VERSION ""

NS_ :

BS_:

BU_: UUT CTRL

BO_ 3221225472 VECTOR__INDEPENDENT_SIG_MSG: 0 Vector__XXX
 SG_ DutyCycle_SP_Input1A : 16|16@1+ (1,0) [0|0] "" Vector__XXX
 SG_ DutyCycle_SP_Input1B : 48|16@1+ (1,0) [0|0] "" Vector__XXX
 SG_ DutyCycle_SP_Input3A : 16|16@1+ (1,0) [0|0] "" Vector__XXX
 SG_ DutyCycle_SP_Input3B : 48|16@1+ (1,0) [0|0] "" Vector__XXX
 SG_ LowBYTE_Counter_1A_Setpoint m87 : 32|16@1+ (1,0) [0|0] "" Vector__XXX
 SG_ LowBYTE_Counter_3A_Setpoint m87 : 48|16@1+ (1,0) [0|0] "" Vector__XXX

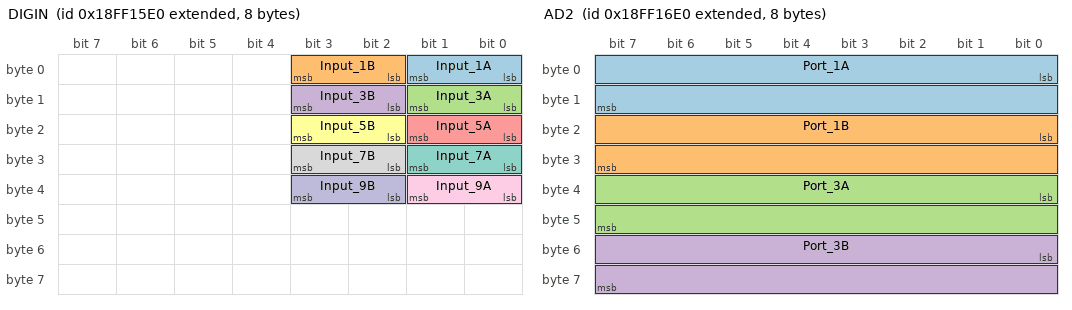
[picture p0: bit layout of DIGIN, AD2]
BO_ 2566854112 DIGIN: 8 UUT
 SG_ Input_1A : 0|2@1+ (1,0) [0|0] "" Vector__XXX
 SG_ Input_1B : 2|2@1+ (1,0) [0|0] "" Vector__XXX
 SG_ Input_3A : 8|2@1+ (1,0) [0|0] "" Vector__XXX
 SG_ Input_3B : 10|2@1+ (1,0) [0|0] "" Vector__XXX
 SG_ Input_5A : 16|2@1+ (1,0) [0|0] "" Vector__XXX
 SG_ Input_5B : 18|2@1+ (1,0) [0|0] "" Vector__XXX
 SG_ Input_7A : 24|2@1+ (1,0) [0|0] "" Vector__XXX
 SG_ Input_7B : 26|2@1+ (1,0) [0|0] "" Vector__XXX
 SG_ Input_9A : 32|2@1+ (1,0) [0|0] "" Vector__XXX
 SG_ Input_9B : 34|2@1+ (1,0) [0|0] "" Vector__XXX

BO_ 2566854368 AD2: 8 UUT
 SG_ Port_1A : 0|16@1+ (0.001,0) [0|0] "" Vector__XXX
 SG_ Port_1B : 16|16@1+ (0.001,0) [0|0] "" Vector__XXX
 SG_ Port_3A : 32|16@1+ (0.001,0) [0|0] "" Vector__XXX
 SG_ Port_3B : 48|16@1+ (0.001,0) [0|0] "" Vector__XXX

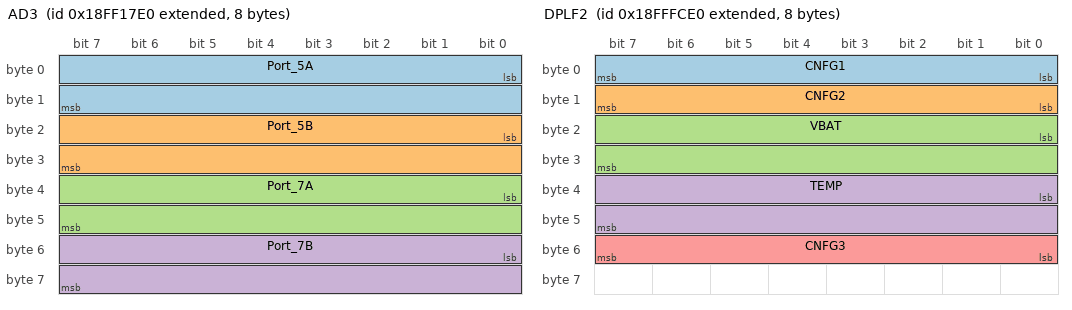
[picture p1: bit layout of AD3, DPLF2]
BO_ 2566854624 AD3: 8 UUT
 SG_ Port_5A : 0|16@1+ (0.001,0) [0|0] "" Vector__XXX
 SG_ Port_5B : 16|16@1+ (0.001,0) [0|0] "" Vector__XXX
 SG_ Port_7A : 32|16@1+ (0.001,0) [0|0] "" Vector__XXX
 SG_ Port_7B : 48|16@1+ (0.001,0) [0|0] "" Vector__XXX

BO_ 2566854880 AD4: 8 UUT
 SG_ Port_9A : 0|16@1+ (0.001,0) [0|0] "" Vector__XXX
 SG_ Port_9B : 16|16@1+ (0.001,0) [0|0] "" Vector__XXX

BO_ 2566855392 FREQ1: 8 UUT
 SG_ Hertz_Count_Input1A : 0|16@1+ (1,0) [0|0] "" Vector__XXX
 SG_ Hertz_Count_Input1B : 32|16@1+ (1,0) [0|0] "" Vector__XXX
 SG_ EncoderValue1 : 0|32@1+ (1,0) [0|0] "" Vector__XXX

BO_ 2566855648 FREQ2: 8 UUT
 SG_ Count_Input3A : 0|16@1+ (1,0) [0|0] "" Vector__XXX
 SG_ Count_Input3B : 32|16@1+ (1,0) [0|0] "" Vector__XXX
 SG_ EncoderValue3 : 0|32@1+ (1,0) [0|0] "" Vector__XXX

BO_ 2565853664 STAT: 8 UUT
 SG_ Software_Version : 0|8@1+ (1,0) [0|0] "" Vector__XXX
 SG_ Software_Revision : 8|8@1+ (1,0) [0|0] "" Vector__XXX
 SG_ Factory_Default_Configuration : 16|2@1+ (1,0) [0|0] "" Vector__XXX
 SG_ Configuration_Saved : 18|2@1+ (1,0) [0|0] "" Vector__XXX
 SG_ Alternate_Configuration_Saved : 20|2@1+ (1,0) [0|0] "" Vector__XXX
 SG_ Node_Alive : 22|2@1+ (1,0) [0|0] "" Vector__XXX
 SG_ Node_Fault_Present : 24|2@1+ (1,0) [0|0] "" Vector__XXX
 SG_ Fault_Counter_Not_Zero : 26|2@1+ (1,0) [0|0] "" Vector__XXX
 SG_ Active_Fault_Code : 32|8@1+ (1,0) [0|0] "" Vector__XXX
 SG_ UserID : 40|8@1+ (1,0) [0|0] "" Vector__XXX
 SG_ CMND_52h_RCVD : 48|2@1+ (1,0) [0|0] "" Vector__XXX
 SG_ CMND_53h_RCVD : 50|2@1+ (1,0) [0|0] "" Vector__XXX
 SG_ CMND_54h_RCVD : 52|2@1+ (1,0) [0|0] "" Vector__XXX
 SG_ CMND_55h_RCVD : 54|2@1+ (1,0) [0|0] "" Vector__XXX
 SG_ CMND_56h_RCVD : 56|2@1+ (1,0) [0|0] "" Vector__XXX
 SG_ CMND_57h_RCVD : 58|2@1+ (1,0) [0|0] "" Vector__XXX
 SG_ Hardware_Dash : 60|4@1+ (1,0) [0|0] "" Vector__XXX

BO_ 2566912992 DPLF1: 8 UUT
 SG_ Input_1_BAUD1 : 0|2@1+ (1,0) [0|0] "" Vector__XXX
 SG_ Input_2_BAUD2 : 2|2@1+ (1,0) [0|0] "" Vector__XXX
 SG_ Input_3_CNFG_IN1 : 4|2@1+ (1,0) [0|0] "" Vector__XXX
 SG_ Input_4_CNFG_IN2 : 6|2@1+ (1,0) [0|0] "" Vector__XXX
 SG_ Input_5_CNFG_IN3 : 8|2@1+ (1,0) [0|0] "" Vector__XXX
 SG_ Input_6_CNFG_IN4 : 10|2@1+ (1,0) [0|0] "" Vector__XXX
 SG_ Input_7_CNFG_IN5 : 12|2@1+ (1,0) [0|0] "" Vector__XXX
 SG_ PowerBusP1 : 14|2@1+ (1,0) [0|0] "" Vector__XXX
 SG_ SpwrStat1 : 16|2@1+ (1,0) [0|0] "" Vector__XXX
 SG_ OutStat2A : 20|2@1+ (1,0) [0|0] "" Vector__XXX
 SG_ OutStat2B : 22|2@1+ (1,0) [0|0] "" Vector__XXX
 SG_ SpwrStat3 : 24|2@1+ (1,0) [0|0] "" Vector__XXX
 SG_ OutStat4A : 28|2@1+ (1,0) [0|0] "" Vector__XXX
 SG_ OutStat4B : 30|2@1+ (1,0) [0|0] "" Vector__XXX
 SG_ SpwrStat5 : 32|2@1+ (1,0) [0|0] "" Vector__XXX
 SG_ OutStat6A : 36|2@1+ (1,0) [0|0] "" Vector__XXX
 SG_ OutStat6B : 38|2@1+ (1,0) [0|0] "" Vector__XXX
 SG_ SpwrStat7 : 40|2@1+ (1,0) [0|0] "" Vector__XXX
 SG_ OutStat8A : 44|2@1+ (1,0) [0|0] "" Vector__XXX
 SG_ OutStat8B : 46|2@1+ (1,0) [0|0] "" Vector__XXX
 SG_ SpwrStat9 : 48|2@1+ (1,0) [0|0] "" Vector__XXX
 SG_ OutStat10A : 52|2@1+ (1,0) [0|0] "" Vector__XXX
 SG_ OutStat10B : 54|2@1+ (1,0) [0|0] "" Vector__XXX
 SG_ Save_Counter : 56|8@1+ (1,0) [0|0] "" Vector__XXX

BO_ 2566913248 DPLF2: 8 UUT
 SG_ CNFG1 : 0|8@1+ (1,0) [0|0] "" Vector__XXX
 SG_ CNFG2 : 8|8@1+ (1,0) [0|0] "" Vector__XXX
 SG_ VBAT : 16|16@1+ (1,0) [0|0] "" Vector__XXX
 SG_ TEMP : 32|16@1+ (1,0) [0|0] "" Vector__XXX
 SG_ CNFG3 : 48|8@1+ (1,0) [0|0] "" Vector__XXX

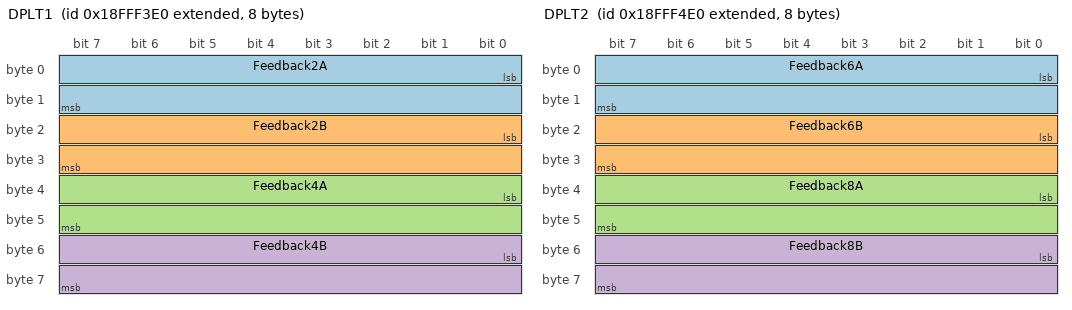
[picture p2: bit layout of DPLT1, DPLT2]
BO_ 2566910944 DPLT1: 8 UUT
 SG_ Feedback2A : 0|16@1+ (0.001,0) [0|0] "" Vector__XXX
 SG_ Feedback2B : 16|16@1+ (0.001,0) [0|0] "" Vector__XXX
 SG_ Feedback4A : 32|16@1+ (0.001,0) [0|0] "" Vector__XXX
 SG_ Feedback4B : 48|16@1+ (0.001,0) [0|0] "" Vector__XXX

BO_ 2566911200 DPLT2: 8 UUT
 SG_ Feedback6A : 0|16@1+ (0.001,0) [0|0] "" Vector__XXX
 SG_ Feedback6B : 16|16@1+ (0.001,0) [0|0] "" Vector__XXX
 SG_ Feedback8A : 32|16@1+ (0.001,0) [0|0] "" Vector__XXX
 SG_ Feedback8B : 48|16@1+ (0.001,0) [0|0] "" Vector__XXX

BO_ 2566911456 DPLT3: 8 UUT
 SG_ Feedback10A : 0|16@1+ (0.001,0) [0|0] "" Vector__XXX
 SG_ Feedback10B : 16|16@1+ (0.001,0) [0|0] "" Vector__XXX

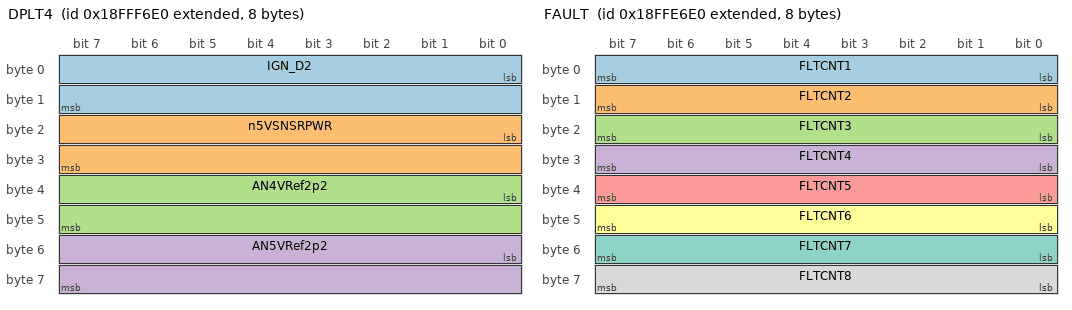
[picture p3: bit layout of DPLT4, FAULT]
BO_ 2566911712 DPLT4: 8 UUT
 SG_ IGN_D2 : 0|16@1- (1,0) [0|0] "" Vector__XXX
 SG_ n5VSNSRPWR : 16|16@1+ (1,0) [0|0] "" Vector__XXX
 SG_ AN4VRef2p2 : 32|16@1+ (1,0) [0|0] "" Vector__XXX
 SG_ AN5VRef2p2 : 48|16@1+ (1,0) [0|0] "" Vector__XXX

BO_ 2566907616 FAULT: 8 UUT
 SG_ FLTCNT1 : 0|8@1+ (1,0) [0|0] "" Vector__XXX
 SG_ FLTCNT2 : 8|8@1+ (1,0) [0|0] "" Vector__XXX
 SG_ FLTCNT3 : 16|8@1+ (1,0) [0|0] "" Vector__XXX
 SG_ FLTCNT4 : 24|8@1+ (1,0) [0|0] "" Vector__XXX
 SG_ FLTCNT5 : 32|8@1+ (1,0) [0|0] "" Vector__XXX
 SG_ FLTCNT6 : 40|8@1+ (1,0) [0|0] "" Vector__XXX
 SG_ FLTCNT7 : 48|8@1+ (1,0) [0|0] "" Vector__XXX
 SG_ FLTCNT8 : 56|8@1+ (1,0) [0|0] "" Vector__XXX
